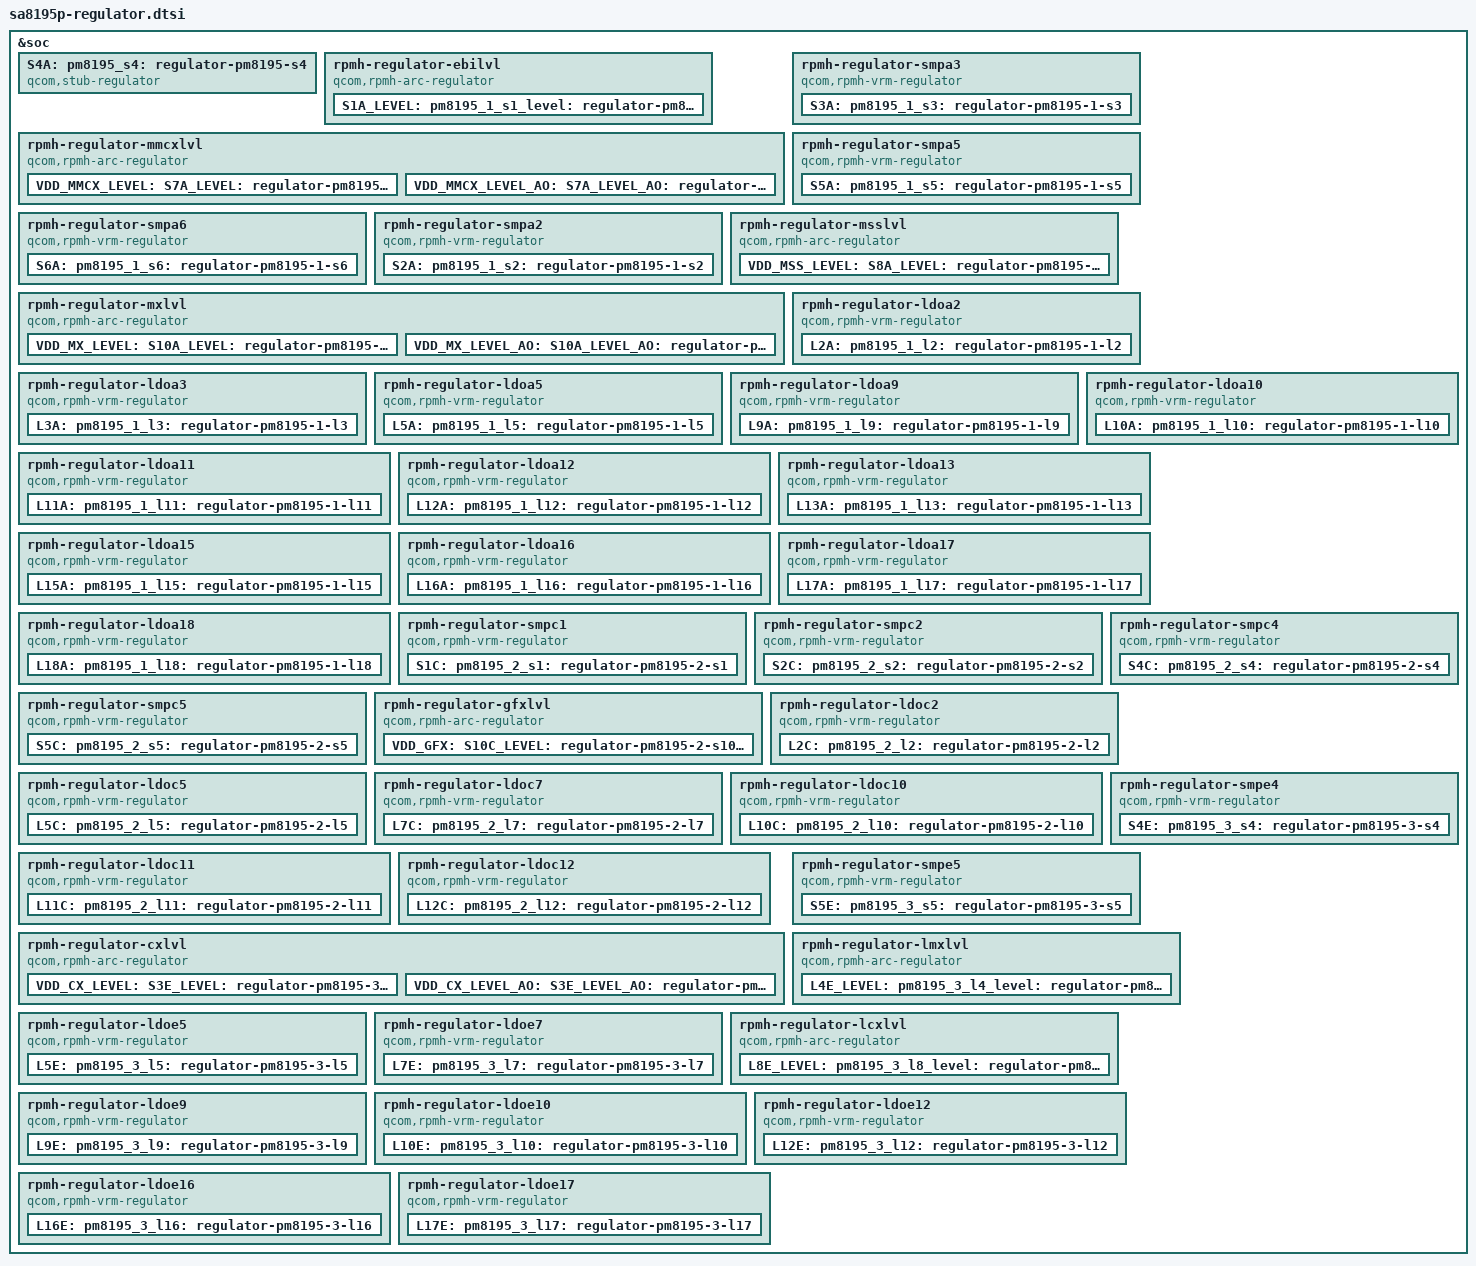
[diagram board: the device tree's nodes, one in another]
/* Copyright (c) 2019-2020, The Linux Foundation. All rights reserved.
 *
 * This program is free software; you can redistribute it and/or modify
 * it under the terms of the GNU General Public License version 2 and
 * only version 2 as published by the Free Software Foundation.
 *
 * This program is distributed in the hope that it will be useful,
 * but WITHOUT ANY WARRANTY; without even the implied warranty of
 * MERCHANTABILITY or FITNESS FOR A PARTICULAR PURPOSE.  See the
 * GNU General Public License for more details.
 */

#include <dt-bindings/regulator/qcom,rpmh-regulator.h>

&soc {
	/* Stub regulator */
	/*
	 * RPMh does not provide support for PM8195 S4 because it is always-on
	 * at 1.8 V in auto mode.  Therefore, use a stub regulator for S4.
	 */
	S4A: pm8195_s4: regulator-pm8195-s4 {
		compatible = "qcom,stub-regulator";
		regulator-name = "pm8195_s4";
		qcom,hpm-min-load = <100000>;
		regulator-min-microvolt = <1800000>;
		regulator-max-microvolt = <1800000>;
	};

	/* PM8195_1 S1 = VDD_EBI supply */
	rpmh-regulator-ebilvl {
		compatible = "qcom,rpmh-arc-regulator";
		mboxes = <&apps_rsc 0>;
		qcom,resource-name = "ebi.lvl";
		S1A_LEVEL: pm8195_1_s1_level: regulator-pm8195-1-s1-level {
			regulator-name = "pm8195_1_s1_level";
			qcom,set = <RPMH_REGULATOR_SET_ALL>;
			regulator-min-microvolt
				= <RPMH_REGULATOR_LEVEL_RETENTION>;
			regulator-max-microvolt
				= <RPMH_REGULATOR_LEVEL_MAX>;
			qcom,init-voltage-level
				= <RPMH_REGULATOR_LEVEL_RETENTION>;
		};
	};

	/* PM8195_1 S2 = VDDCX_MM supply */
	rpmh-regulator-mmcxlvl {
		compatible = "qcom,rpmh-arc-regulator";
		mboxes = <&apps_rsc 0>;
		qcom,resource-name = "mmcx.lvl";

		VDD_MMCX_LEVEL:
		S7A_LEVEL: pm8195_1_s7_level: regulator-pm8195-1-s7-level {
			regulator-name = "pm8195_1_s7_level";
			qcom,set = <RPMH_REGULATOR_SET_ALL>;
			regulator-min-microvolt
				= <RPMH_REGULATOR_LEVEL_RETENTION>;
			regulator-max-microvolt
				= <RPMH_REGULATOR_LEVEL_MAX>;
			qcom,init-voltage-level
				= <RPMH_REGULATOR_LEVEL_RETENTION>;
		};

		VDD_MMCX_LEVEL_AO: S7A_LEVEL_AO:
		pm8195_1_s7_level_ao: regulator-pm8195-1-s7-level-ao {
			regulator-name = "pm8195_1_s7_level_ao";
			qcom,set = <RPMH_REGULATOR_SET_ACTIVE>;
			regulator-min-microvolt
				= <RPMH_REGULATOR_LEVEL_RETENTION>;
			regulator-max-microvolt
				= <RPMH_REGULATOR_LEVEL_MAX>;
			qcom,init-voltage-level
				= <RPMH_REGULATOR_LEVEL_LOW_SVS>;
		};
	};

	rpmh-regulator-smpa3 {
		compatible = "qcom,rpmh-vrm-regulator";
		mboxes = <&apps_rsc 0>;
		qcom,resource-name = "smpa3";
		S3A: pm8195_1_s3: regulator-pm8195-1-s3 {
			regulator-name = "pm8195_1_s3";
			qcom,set = <RPMH_REGULATOR_SET_ALL>;
			regulator-min-microvolt = <788000>;
			regulator-max-microvolt = <969000>;
			qcom,init-voltage = <788000>;
		};
	};

	rpmh-regulator-smpa5 {
		compatible = "qcom,rpmh-vrm-regulator";
		mboxes = <&apps_rsc 0>;
		qcom,resource-name = "smpa5";
		S5A: pm8195_1_s5: regulator-pm8195-1-s5 {
			regulator-name = "pm8195_1_s5";
			qcom,set = <RPMH_REGULATOR_SET_ALL>;
			regulator-min-microvolt = <900000>;
			regulator-max-microvolt = <1000000>;
			qcom,init-voltage = <900000>;
		};
	};

	rpmh-regulator-smpa6 {
		compatible = "qcom,rpmh-vrm-regulator";
		mboxes = <&apps_rsc 0>;
		qcom,resource-name = "smpa6";
		S6A: pm8195_1_s6: regulator-pm8195-1-s6 {
			regulator-name = "pm8195_1_s6";
			qcom,set = <RPMH_REGULATOR_SET_ALL>;
			regulator-min-microvolt = <800000>;
			regulator-max-microvolt = <1300000>;
			qcom,init-voltage = <800000>;
		};
	};

	rpmh-regulator-smpa2 {
		compatible = "qcom,rpmh-vrm-regulator";
		mboxes = <&apps_rsc 0>;
		qcom,resource-name = "smpa2";
		S2A: pm8195_1_s2: regulator-pm8195-1-s2 {
			regulator-name = "pm8195_1_s2";
			qcom,set = <RPMH_REGULATOR_SET_ALL>;
			regulator-min-microvolt = <1179000>;
			regulator-max-microvolt = <1379000>;
			qcom,init-voltage = <1179000>;
		};
	};

	/* pm8195_1 S8 = VDD_MODEM supply */
	rpmh-regulator-msslvl {
		compatible = "qcom,rpmh-arc-regulator";
		mboxes = <&apps_rsc 0>;
		qcom,resource-name = "mss.lvl";
		VDD_MSS_LEVEL:
		S8A_LEVEL: pm8195_1_s8_level: regulator-pm8195-1-s8-level {
			regulator-name = "pm8195_1_s8_level";
			qcom,set = <RPMH_REGULATOR_SET_ALL>;
			regulator-min-microvolt
				= <RPMH_REGULATOR_LEVEL_RETENTION>;
			regulator-max-microvolt
				= <RPMH_REGULATOR_LEVEL_MAX>;
			qcom,init-voltage-level
				= <RPMH_REGULATOR_LEVEL_RETENTION>;
		};
	};

	/* PM8195_1 S10 = VDD_MX supply */
	rpmh-regulator-mxlvl {
		compatible = "qcom,rpmh-arc-regulator";
		mboxes = <&apps_rsc 0>;
		qcom,resource-name = "mx.lvl";

		VDD_MX_LEVEL:
		S10A_LEVEL: pm8195_1_s10_level: regulator-pm8195-1-s10-level {
			regulator-name = "pm8195_1_s10_level";
			qcom,set = <RPMH_REGULATOR_SET_ALL>;
			regulator-min-microvolt
				= <RPMH_REGULATOR_LEVEL_RETENTION>;
			regulator-max-microvolt
				= <RPMH_REGULATOR_LEVEL_MAX>;
			qcom,init-voltage-level
				= <RPMH_REGULATOR_LEVEL_RETENTION>;
		};

		VDD_MX_LEVEL_AO: S10A_LEVEL_AO:
		pm8195_1_s10_level_ao: regulator-pm8195-1-s10-level-ao {
			regulator-name = "pm8195_1_s10_level_ao";
			qcom,set = <RPMH_REGULATOR_SET_ACTIVE>;
			regulator-min-microvolt
				= <RPMH_REGULATOR_LEVEL_RETENTION>;
			regulator-max-microvolt
				= <RPMH_REGULATOR_LEVEL_MAX>;
			qcom,init-voltage-level
				= <RPMH_REGULATOR_LEVEL_RETENTION>;
		};
	};

	rpmh-regulator-ldoa2 {
		compatible = "qcom,rpmh-vrm-regulator";
		mboxes = <&apps_rsc 0>;
		qcom,resource-name = "ldoa2";
		qcom,regulator-type = "pmic5-ldo";
		qcom,supported-modes =
			<RPMH_REGULATOR_MODE_LPM
			 RPMH_REGULATOR_MODE_HPM>;
		qcom,mode-threshold-currents = <0 1>;
		L2A: pm8195_1_l2: regulator-pm8195-1-l2 {
			regulator-name = "pm8195_1_l2";
			qcom,set = <RPMH_REGULATOR_SET_ALL>;
			regulator-min-microvolt = <1800000>;
			regulator-max-microvolt = <3300000>;
			qcom,init-voltage = <1800000>;
			qcom,init-mode = <RPMH_REGULATOR_MODE_LPM>;
		};
	};

	rpmh-regulator-ldoa3 {
		compatible = "qcom,rpmh-vrm-regulator";
		mboxes = <&apps_rsc 0>;
		qcom,resource-name = "ldoa3";
		qcom,regulator-type = "pmic5-ldo";
		qcom,supported-modes =
			<RPMH_REGULATOR_MODE_LPM
			 RPMH_REGULATOR_MODE_HPM>;
		qcom,mode-threshold-currents = <0 1>;
		L3A: pm8195_1_l3: regulator-pm8195-1-l3 {
			regulator-name = "pm8195_1_l3";
			qcom,set = <RPMH_REGULATOR_SET_ALL>;
			regulator-min-microvolt = <760000>;
			regulator-max-microvolt = <816000>;
			qcom,init-voltage = <760000>;
			qcom,init-mode = <RPMH_REGULATOR_MODE_LPM>;
		};
	};

	rpmh-regulator-ldoa5 {
		compatible = "qcom,rpmh-vrm-regulator";
		mboxes = <&apps_rsc 0>;
		qcom,resource-name = "ldoa5";
		qcom,regulator-type = "pmic5-ldo";
		qcom,supported-modes =
			<RPMH_REGULATOR_MODE_LPM
			 RPMH_REGULATOR_MODE_HPM>;
		qcom,mode-threshold-currents = <0 1>;
		L5A: pm8195_1_l5: regulator-pm8195-1-l5 {
			regulator-name = "pm8195_1_l5";
			qcom,set = <RPMH_REGULATOR_SET_ALL>;
			regulator-min-microvolt = <720000>;
			regulator-max-microvolt = <880000>;
			qcom,init-voltage = <720000>;
			qcom,init-mode = <RPMH_REGULATOR_MODE_LPM>;
		};
	};

	/* DSI display 1.2 */
	rpmh-regulator-ldoa9 {
		compatible = "qcom,rpmh-vrm-regulator";
		mboxes = <&apps_rsc 0>;
		qcom,resource-name = "ldoa9";
		qcom,regulator-type = "pmic5-ldo";
		qcom,supported-modes =
			<RPMH_REGULATOR_MODE_LPM
			 RPMH_REGULATOR_MODE_HPM>;
		qcom,mode-threshold-currents = <0 1>;
		L9A: pm8195_1_l9: regulator-pm8195-1-l9 {
			regulator-name = "pm8195_1_l9";
			qcom,set = <RPMH_REGULATOR_SET_ALL>;
			regulator-min-microvolt = <1150000>;
			regulator-max-microvolt = <1250000>;
			qcom,init-voltage = <1150000>;
			qcom,init-mode = <RPMH_REGULATOR_MODE_LPM>;
		};
	};

	rpmh-regulator-ldoa10 {
		compatible = "qcom,rpmh-vrm-regulator";
		mboxes = <&apps_rsc 0>;
		qcom,resource-name = "ldoa10";
		qcom,regulator-type = "pmic5-ldo";
		qcom,supported-modes =
			<RPMH_REGULATOR_MODE_LPM
			 RPMH_REGULATOR_MODE_HPM>;
		qcom,mode-threshold-currents = <0 1>;
		L10A: pm8195_1_l10: regulator-pm8195-1-l10 {
			regulator-name = "pm8195_1_l10";
			qcom,set = <RPMH_REGULATOR_SET_ALL>;
			regulator-min-microvolt = <2700000>;
			regulator-max-microvolt = <3544000>;
			qcom,init-voltage = <2700000>;
			qcom,init-mode = <RPMH_REGULATOR_MODE_LPM>;
		};
	};

	rpmh-regulator-ldoa11 {
		compatible = "qcom,rpmh-vrm-regulator";
		mboxes = <&apps_rsc 0>;
		qcom,resource-name = "ldoa11";
		qcom,regulator-type = "pmic5-ldo";
		qcom,supported-modes =
			<RPMH_REGULATOR_MODE_LPM
			 RPMH_REGULATOR_MODE_HPM>;
		qcom,mode-threshold-currents = <0 1>;
		L11A: pm8195_1_l11: regulator-pm8195-1-l11 {
			regulator-name = "pm8195_1_l11";
			qcom,set = <RPMH_REGULATOR_SET_ALL>;
			regulator-min-microvolt = <1100000>;
			regulator-max-microvolt = <1300000>;
			qcom,init-voltage = <1100000>;
			qcom,init-mode = <RPMH_REGULATOR_MODE_LPM>;
		};
	};

	rpmh-regulator-ldoa12 {
		compatible = "qcom,rpmh-vrm-regulator";
		mboxes = <&apps_rsc 0>;
		qcom,resource-name = "ldoa12";
		qcom,regulator-type = "pmic5-ldo";
		qcom,supported-modes =
			<RPMH_REGULATOR_MODE_LPM
			 RPMH_REGULATOR_MODE_HPM>;
		qcom,mode-threshold-currents = <0 1>;
		L12A: pm8195_1_l12: regulator-pm8195-1-l12 {
			regulator-name = "pm8195_1_l12";
			qcom,set = <RPMH_REGULATOR_SET_ALL>;
			regulator-min-microvolt = <1800000>;
			regulator-max-microvolt = <1890000>;
			qcom,init-voltage = <1800000>;
			qcom,init-mode = <RPMH_REGULATOR_MODE_LPM>;
			regulator-always-on;
		};
	};

	rpmh-regulator-ldoa13 {
		compatible = "qcom,rpmh-vrm-regulator";
		mboxes = <&apps_rsc 0>;
		qcom,resource-name = "ldoa13";
		qcom,regulator-type = "pmic5-ldo";
		qcom,supported-modes =
			<RPMH_REGULATOR_MODE_LPM
			RPMH_REGULATOR_MODE_HPM>;
		qcom,mode-threshold-currents = <0 1>;
		L13A: pm8195_1_l13: regulator-pm8195-1-l13 {
			regulator-name = "pm8195_1_l13";
			qcom,set = <RPMH_REGULATOR_SET_ALL>;
			regulator-min-microvolt = <2500000>;
			regulator-max-microvolt = <2900000>;
			qcom,init-voltage = <2500000>;
			qcom,init-mode = <RPMH_REGULATOR_MODE_LPM>;
		};
	};

	rpmh-regulator-ldoa15 {
		compatible = "qcom,rpmh-vrm-regulator";
		mboxes = <&apps_rsc 0>;
		qcom,resource-name = "ldoa15";
		qcom,regulator-type = "pmic5-ldo";
		qcom,supported-modes =
			<RPMH_REGULATOR_MODE_LPM
			 RPMH_REGULATOR_MODE_HPM>;
		qcom,mode-threshold-currents = <0 1>;
		L15A: pm8195_1_l15: regulator-pm8195-1-l15 {
			regulator-name = "pm8195_1_l15";
			qcom,set = <RPMH_REGULATOR_SET_ALL>;
			regulator-min-microvolt = <1700000>;
			regulator-max-microvolt = <1751000>;
			qcom,init-voltage = <1700000>;
			qcom,init-mode = <RPMH_REGULATOR_MODE_LPM>;
		};
	};

	rpmh-regulator-ldoa16 {
		compatible = "qcom,rpmh-vrm-regulator";
		mboxes = <&apps_rsc 0>;
		qcom,resource-name = "ldoa16";
		qcom,regulator-type = "pmic5-ldo";
		qcom,supported-modes =
			<RPMH_REGULATOR_MODE_LPM
			 RPMH_REGULATOR_MODE_HPM>;
		qcom,mode-threshold-currents = <0 1>;
		L16A: pm8195_1_l16: regulator-pm8195-1-l16 {
			regulator-name = "pm8195_1_l16";
			qcom,set = <RPMH_REGULATOR_SET_ALL>;
			regulator-min-microvolt = <2500000>;
			regulator-max-microvolt = <2900000>;
			qcom,init-voltage = <2500000>;
			qcom,init-mode = <RPMH_REGULATOR_MODE_LPM>;
		};
	};


	rpmh-regulator-ldoa17 {
		compatible = "qcom,rpmh-vrm-regulator";
		mboxes = <&apps_rsc 0>;
		qcom,resource-name = "ldoa17";
		qcom,regulator-type = "pmic5-ldo";
		qcom,supported-modes =
			<RPMH_REGULATOR_MODE_LPM
			 RPMH_REGULATOR_MODE_HPM>;
		qcom,mode-threshold-currents = <0 1>;
		L17A: pm8195_1_l17: regulator-pm8195-1-l17 {
			regulator-name = "pm8195_1_l17";
			qcom,set = <RPMH_REGULATOR_SET_ALL>;
			regulator-min-microvolt = <1700000>;
			regulator-max-microvolt = <3544000>;
			qcom,init-voltage = <1700000>;
			qcom,init-mode = <RPMH_REGULATOR_MODE_LPM>;
		};
	};

	rpmh-regulator-ldoa18 {
		compatible = "qcom,rpmh-vrm-regulator";
		mboxes = <&apps_rsc 0>;
		qcom,resource-name = "ldoa18";
		qcom,regulator-type = "pmic5-ldo";
		qcom,supported-modes =
			<RPMH_REGULATOR_MODE_LPM
			 RPMH_REGULATOR_MODE_HPM>;
		qcom,mode-threshold-currents = <0 1>;
		L18A: pm8195_1_l18: regulator-pm8195-1-l18 {
			regulator-name = "pm8195_1_l18";
			qcom,set = <RPMH_REGULATOR_SET_ALL>;
			regulator-min-microvolt = <831000>;
			regulator-max-microvolt = <918000>;
			qcom,init-voltage = <831000>;
			qcom,init-mode = <RPMH_REGULATOR_MODE_LPM>;
		};
	};

	rpmh-regulator-smpc1 {
		compatible = "qcom,rpmh-vrm-regulator";
		mboxes = <&apps_rsc 0>;
		qcom,resource-name = "smpc1";
		S1C: pm8195_2_s1: regulator-pm8195-2-s1 {
			regulator-name = "pm8195_2_s1";
			qcom,set = <RPMH_REGULATOR_SET_ALL>;
			regulator-min-microvolt = <570000>;
			regulator-max-microvolt = <648000>;
			qcom,init-voltage = <570000>;
		};
	};

	rpmh-regulator-smpc2 {
		compatible = "qcom,rpmh-vrm-regulator";
		mboxes = <&apps_rsc 0>;
		qcom,resource-name = "smpc2";
		S2C: pm8195_2_s2: regulator-pm8195-2-s2 {
			regulator-name = "pm8195_2_s2";
			qcom,set = <RPMH_REGULATOR_SET_ALL>;
			regulator-min-microvolt = <1060000>;
			regulator-max-microvolt = <1170000>;
			qcom,init-voltage = <1060000>;
		};
	};

	rpmh-regulator-smpc4 {
		compatible = "qcom,rpmh-vrm-regulator";
		mboxes = <&apps_rsc 0>;
		qcom,resource-name = "smpc4";
		S4C: pm8195_2_s4: regulator-pm8195-2-s4 {
			regulator-name = "pm8195_2_s4";
			qcom,set = <RPMH_REGULATOR_SET_ALL>;
			regulator-min-microvolt = <1620000>;
			regulator-max-microvolt = <1900000>;
			qcom,init-voltage = <1620000>;
		};
	};

	rpmh-regulator-smpc5 {
		compatible = "qcom,rpmh-vrm-regulator";
		mboxes = <&apps_rsc 0>;
		qcom,resource-name = "smpc5";
		S5C: pm8195_2_s5: regulator-pm8195-2-s5 {
			regulator-name = "pm8195_2_s5";
			qcom,set = <RPMH_REGULATOR_SET_ALL>;
			regulator-min-microvolt = <1713000>;
			regulator-max-microvolt = <2040000>;
			qcom,init-voltage = <1713000>;
		};
	};

	/* PM8195_2 S10 + S9 + S8 + S7 + S6 = VDD_GFX supply */
	rpmh-regulator-gfxlvl {
		compatible = "qcom,rpmh-arc-regulator";
		mboxes = <&apps_rsc 0>;
		qcom,resource-name = "gfx.lvl";
		VDD_GFX:
		S10C_LEVEL: pm8195_2_s10_level: regulator-pm8195-2-s10-level {
			regulator-name = "pm8195_2_s10_level";
			qcom,set = <RPMH_REGULATOR_SET_ALL>;
			regulator-min-microvolt
				= <RPMH_REGULATOR_LEVEL_RETENTION>;
			regulator-max-microvolt
				= <RPMH_REGULATOR_LEVEL_MAX>;
			qcom,init-voltage-level
				= <RPMH_REGULATOR_LEVEL_RETENTION>;
		};
	};

	rpmh-regulator-ldoc2 {
		compatible = "qcom,rpmh-vrm-regulator";
		mboxes = <&apps_rsc 0>;
		qcom,resource-name = "ldoc2";
		qcom,regulator-type = "pmic5-ldo";
		qcom,supported-modes =
			<RPMH_REGULATOR_MODE_LPM
			 RPMH_REGULATOR_MODE_HPM>;
		qcom,mode-threshold-currents = <0 1>;
		L2C: pm8195_2_l2: regulator-pm8195-2-l2 {
			regulator-name = "pm8195_2_l2";
			qcom,set = <RPMH_REGULATOR_SET_ALL>;
			regulator-min-microvolt = <1800000>;
			regulator-max-microvolt = <3330000>;
			qcom,init-voltage = <1800000>;
			qcom,init-mode = <RPMH_REGULATOR_MODE_LPM>;
		};
	};

	rpmh-regulator-ldoc5 {
		compatible = "qcom,rpmh-vrm-regulator";
		mboxes = <&apps_rsc 0>;
		qcom,resource-name = "ldoc5";
		qcom,regulator-type = "pmic5-ldo";
		qcom,supported-modes =
			<RPMH_REGULATOR_MODE_LPM
			 RPMH_REGULATOR_MODE_HPM>;
		qcom,mode-threshold-currents = <0 1>;
		L5C: pm8195_2_l5: regulator-pm8195-2-l5 {
			regulator-name = "pm8195_2_l5";
			qcom,set = <RPMH_REGULATOR_SET_ALL>;
			regulator-min-microvolt = <1200000>;
			regulator-max-microvolt = <1200000>;
			qcom,init-voltage = <1200000>;
			qcom,init-mode = <RPMH_REGULATOR_MODE_LPM>;
		};
	};

	rpmh-regulator-ldoc7 {
		compatible = "qcom,rpmh-vrm-regulator";
		mboxes = <&apps_rsc 0>;
		qcom,resource-name = "ldoc7";
		qcom,regulator-type = "pmic5-ldo";
		qcom,supported-modes =
			<RPMH_REGULATOR_MODE_LPM
			 RPMH_REGULATOR_MODE_HPM>;
		qcom,mode-threshold-currents = <0 1>;
		L7C: pm8195_2_l7: regulator-pm8195-2-l7 {
			regulator-name = "pm8195_2_l7";
			qcom,set = <RPMH_REGULATOR_SET_ALL>;
			regulator-min-microvolt = <1800000>;
			regulator-max-microvolt = <2040000>;
			qcom,init-voltage = <1800000>;
			qcom,init-mode = <RPMH_REGULATOR_MODE_LPM>;
		};
	};

	rpmh-regulator-ldoc10 {
		compatible = "qcom,rpmh-vrm-regulator";
		mboxes = <&apps_rsc 0>;
		qcom,resource-name = "ldoc10";
		qcom,regulator-type = "pmic5-ldo";
		qcom,supported-modes =
			<RPMH_REGULATOR_MODE_LPM
			 RPMH_REGULATOR_MODE_HPM>;
		qcom,mode-threshold-currents = <0 1>;
		L10C: pm8195_2_l10: regulator-pm8195-2-l10 {
			regulator-name = "pm8195_2_l10";
			qcom,set = <RPMH_REGULATOR_SET_ALL>;
			regulator-min-microvolt = <1620000>;
			regulator-max-microvolt = <3300000>;
			qcom,init-voltage = <1620000>;
			qcom,init-mode = <RPMH_REGULATOR_MODE_LPM>;
		};
	};

	rpmh-regulator-ldoc11 {
		compatible = "qcom,rpmh-vrm-regulator";
		mboxes = <&apps_rsc 0>;
		qcom,resource-name = "ldoc11";
		qcom,regulator-type = "pmic5-ldo";
		qcom,supported-modes =
			<RPMH_REGULATOR_MODE_LPM
			 RPMH_REGULATOR_MODE_HPM>;
		qcom,mode-threshold-currents = <0 1>;
		L11C: pm8195_2_l11: regulator-pm8195-2-l11 {
			regulator-name = "pm8195_2_l11";
			qcom,set = <RPMH_REGULATOR_SET_ALL>;
			regulator-min-microvolt = <1144000>;
			regulator-max-microvolt = <1236000>;
			qcom,init-voltage = <1144000>;
			qcom,init-mode = <RPMH_REGULATOR_MODE_LPM>;
		};
	};

	rpmh-regulator-ldoc12 {
		compatible = "qcom,rpmh-vrm-regulator";
		mboxes = <&apps_rsc 0>;
		qcom,resource-name = "ldoc12";
		qcom,regulator-type = "pmic5-ldo";
		qcom,supported-modes =
			<RPMH_REGULATOR_MODE_LPM
			 RPMH_REGULATOR_MODE_HPM>;
		qcom,mode-threshold-currents = <0 1>;
		L12C: pm8195_2_l12: regulator-pm8195-2-l12 {
			regulator-name = "pm8195_2_l12";
			qcom,set = <RPMH_REGULATOR_SET_ALL>;
			regulator-min-microvolt = <1700000>;
			regulator-max-microvolt = <1900000>;
			qcom,init-voltage = <1700000>;
			qcom,init-mode = <RPMH_REGULATOR_MODE_LPM>;
		};
	};


	/* PM8195_3 S3 + S2 + S1 = VDD_CX supply */
	rpmh-regulator-cxlvl {
		compatible = "qcom,rpmh-arc-regulator";
		mboxes = <&apps_rsc 0>;
		qcom,resource-name = "cx.lvl";
		pm8195_3_s3_level-parent-supply = <&VDD_MX_LEVEL>;
		pm8195_3_s3_level_ao-parent-supply = <&VDD_MX_LEVEL_AO>;

		VDD_CX_LEVEL:
		S3E_LEVEL: pm8195_3_s3_level: regulator-pm8195-3-s3-level {
			regulator-name = "pm8195_3_s3_level";
			qcom,set = <RPMH_REGULATOR_SET_ALL>;
			regulator-min-microvolt
				= <RPMH_REGULATOR_LEVEL_RETENTION>;
			regulator-max-microvolt
				= <RPMH_REGULATOR_LEVEL_MAX>;
			qcom,init-voltage-level
				= <RPMH_REGULATOR_LEVEL_RETENTION>;
			qcom,min-dropout-voltage-level = <(-1)>;
		};

		VDD_CX_LEVEL_AO: S3E_LEVEL_AO:
		pm8195_3_s3_level_ao: regulator-pm8195-3-s3-level-ao {
			regulator-name = "pm8195_3_s3_level_ao";
			qcom,set = <RPMH_REGULATOR_SET_ACTIVE>;
			regulator-min-microvolt
				= <RPMH_REGULATOR_LEVEL_RETENTION>;
			regulator-max-microvolt
				= <RPMH_REGULATOR_LEVEL_MAX>;
			qcom,init-voltage-level
				= <RPMH_REGULATOR_LEVEL_RETENTION>;
			qcom,min-dropout-voltage-level = <(-1)>;
		};
	};

	rpmh-regulator-smpe4 {
		compatible = "qcom,rpmh-vrm-regulator";
		mboxes = <&apps_rsc 0>;
		qcom,resource-name = "smpe4";
		S4E: pm8195_3_s4: regulator-pm8195-3-s4 {
			regulator-name = "pm8195_3_s4";
			qcom,set = <RPMH_REGULATOR_SET_ALL>;
			regulator-min-microvolt = <402000>;
			regulator-max-microvolt = <1980000>;
			qcom,init-voltage = <402000>;
		};
	};

	rpmh-regulator-smpe5 {
		compatible = "qcom,rpmh-vrm-regulator";
		mboxes = <&apps_rsc 0>;
		qcom,resource-name = "smpe5";
		S5E: pm8195_3_s5: regulator-pm8195-3-s5 {
			regulator-name = "pm8195_3_s5";
			qcom,set = <RPMH_REGULATOR_SET_ALL>;
			regulator-min-microvolt = <1811000>;
			regulator-max-microvolt = <2040000>;
			qcom,init-voltage = <1811000>;
		};
	};

	/* PM8195_3 L4 - LPI_MX supply */
	rpmh-regulator-lmxlvl {
		compatible = "qcom,rpmh-arc-regulator";
		mboxes = <&apps_rsc 0>;
		qcom,resource-name = "lmx.lvl";
		L4E_LEVEL: pm8195_3_l4_level: regulator-pm8195-3-l4 {
			regulator-name = "pm8195_3_l4_level";
			qcom,set = <RPMH_REGULATOR_SET_ALL>;
			regulator-min-microvolt =
					<RPMH_REGULATOR_LEVEL_RETENTION>;
			regulator-max-microvolt =
					<RPMH_REGULATOR_LEVEL_MAX>;
			qcom,init-voltage-level =
					<RPMH_REGULATOR_LEVEL_RETENTION>;
		};
	};

	rpmh-regulator-ldoe5 {
		compatible = "qcom,rpmh-vrm-regulator";
		mboxes = <&apps_rsc 0>;
		qcom,resource-name = "ldoe5";
		qcom,regulator-type = "pmic5-ldo";
		qcom,supported-modes =
			<RPMH_REGULATOR_MODE_LPM
			 RPMH_REGULATOR_MODE_HPM>;
		qcom,mode-threshold-currents = <0 1>;
		L5E: pm8195_3_l5: regulator-pm8195-3-l5 {
			regulator-name = "pm8195_3_l5";
			qcom,set = <RPMH_REGULATOR_SET_ALL>;
			regulator-min-microvolt = <800000>;
			regulator-max-microvolt = <920000>;
			qcom,init-voltage = <800000>;
			qcom,init-mode = <RPMH_REGULATOR_MODE_LPM>;
		};
	};

	rpmh-regulator-ldoe7 {
		compatible = "qcom,rpmh-vrm-regulator";
		mboxes = <&apps_rsc 0>;
		qcom,resource-name = "ldoe7";
		qcom,regulator-type = "pmic5-ldo";
		qcom,supported-modes =
			<RPMH_REGULATOR_MODE_LPM
			 RPMH_REGULATOR_MODE_HPM>;
		qcom,mode-threshold-currents = <0 1>;
		L7E: pm8195_3_l7: regulator-pm8195-3-l7 {
			regulator-name = "pm8195_3_l7";
			qcom,set = <RPMH_REGULATOR_SET_ALL>;
			regulator-min-microvolt = <1700000>;
			regulator-max-microvolt = <1950000>;
			qcom,init-voltage = <1700000>;
			qcom,init-mode = <RPMH_REGULATOR_MODE_LPM>;
		};
	};

	/* pm8195_3 L8 - LPI_CX supply */
	rpmh-regulator-lcxlvl {
		compatible = "qcom,rpmh-arc-regulator";
		mboxes = <&apps_rsc 0>;
		qcom,resource-name = "lcx.lvl";
		L8E_LEVEL: pm8195_3_l8_level: regulator-pm8195-3-l8 {
			regulator-name = "pm8195_3_l8_level";
			qcom,set = <RPMH_REGULATOR_SET_ALL>;
			regulator-min-microvolt =
					<RPMH_REGULATOR_LEVEL_RETENTION>;
			regulator-max-microvolt =
					<RPMH_REGULATOR_LEVEL_MAX>;
			qcom,init-voltage-level =
					<RPMH_REGULATOR_LEVEL_RETENTION>;
		};
	};

	rpmh-regulator-ldoe9 {
		compatible = "qcom,rpmh-vrm-regulator";
		mboxes = <&apps_rsc 0>;
		qcom,resource-name = "ldoe9";
		qcom,regulator-type = "pmic5-ldo";
		qcom,supported-modes =
			<RPMH_REGULATOR_MODE_LPM
			 RPMH_REGULATOR_MODE_HPM>;
		qcom,mode-threshold-currents = <0 1>;
		L9E: pm8195_3_l9: regulator-pm8195-3-l9 {
			regulator-name = "pm8195_3_l9";
			qcom,set = <RPMH_REGULATOR_SET_ALL>;
			regulator-min-microvolt = <830000>;
			regulator-max-microvolt = <920000>;
			qcom,init-voltage = <830000>;
			qcom,init-mode = <RPMH_REGULATOR_MODE_LPM>;
		};
	};

	rpmh-regulator-ldoe10 {
		compatible = "qcom,rpmh-vrm-regulator";
		mboxes = <&apps_rsc 0>;
		qcom,resource-name = "ldoe10";
		qcom,regulator-type = "pmic5-ldo";
		qcom,supported-modes =
			<RPMH_REGULATOR_MODE_LPM
			 RPMH_REGULATOR_MODE_HPM>;
		qcom,mode-threshold-currents = <0 1>;
		L10E: pm8195_3_l10: regulator-pm8195-3-l10 {
			regulator-name = "pm8195_3_l10";
			qcom,set = <RPMH_REGULATOR_SET_ALL>;
			regulator-min-microvolt = <2500000>;
			regulator-max-microvolt = <3544000>;
			qcom,init-voltage = <2500000>;
			qcom,init-mode = <RPMH_REGULATOR_MODE_LPM>;
		};
	};

	rpmh-regulator-ldoe12 {
		compatible = "qcom,rpmh-vrm-regulator";
		mboxes = <&apps_rsc 0>;
		qcom,resource-name = "ldoe12";
		qcom,regulator-type = "pmic5-ldo";
		qcom,supported-modes =
			<RPMH_REGULATOR_MODE_LPM
			 RPMH_REGULATOR_MODE_HPM>;
		qcom,mode-threshold-currents = <0 1>;
		L12E: pm8195_3_l12: regulator-pm8195-3-l12 {
			regulator-name = "pm8195_3_l12";
			qcom,set = <RPMH_REGULATOR_SET_ALL>;
			regulator-min-microvolt = <1800000>;
			regulator-max-microvolt = <1800000>;
			qcom,init-voltage = <1800000>;
			qcom,init-mode = <RPMH_REGULATOR_MODE_LPM>;
		};
	};

	rpmh-regulator-ldoe16 {
		compatible = "qcom,rpmh-vrm-regulator";
		mboxes = <&apps_rsc 0>;
		qcom,resource-name = "ldoe16";
		qcom,regulator-type = "pmic5-ldo";
		qcom,supported-modes =
			<RPMH_REGULATOR_MODE_LPM
			 RPMH_REGULATOR_MODE_HPM>;
		qcom,mode-threshold-currents = <0 1>;
		L16E: pm8195_3_l16: regulator-pm8195-3-l16 {
			regulator-name = "pm8195_3_l16";
			qcom,set = <RPMH_REGULATOR_SET_ALL>;
			regulator-min-microvolt = <2921000>;
			regulator-max-microvolt = <3300000>;
			qcom,init-voltage = <2921000>;
			qcom,init-mode = <RPMH_REGULATOR_MODE_LPM>;
		};
	};


	rpmh-regulator-ldoe17 {
		compatible = "qcom,rpmh-vrm-regulator";
		mboxes = <&apps_rsc 0>;
		qcom,resource-name = "ldoe17";
		qcom,regulator-type = "pmic5-ldo";
		qcom,supported-modes =
			<RPMH_REGULATOR_MODE_LPM
			 RPMH_REGULATOR_MODE_HPM>;
		qcom,mode-threshold-currents = <0 1>;
		L17E: pm8195_3_l17: regulator-pm8195-3-l17 {
			regulator-name = "pm8195_3_l17";
			qcom,set = <RPMH_REGULATOR_SET_ALL>;
			regulator-min-microvolt = <2900000>;
			regulator-max-microvolt = <3300000>;
			qcom,init-voltage = <2900000>;
			qcom,init-mode = <RPMH_REGULATOR_MODE_LPM>;
		};
	};
};
